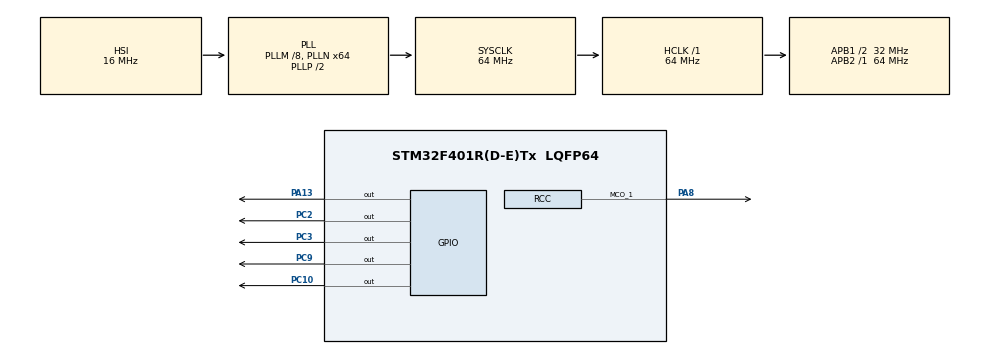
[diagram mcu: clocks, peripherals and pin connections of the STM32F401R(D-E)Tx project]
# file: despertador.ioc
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Mcu.Family=STM32F4
Mcu.Name=STM32F401R(D-E)Tx
Mcu.Package=LQFP64
NVIC.PriorityGroup=NVIC_PRIORITYGROUP_0
NVIC.RTC_WKUP_IRQn=true\:0\:0\:false\:false\:true\:true\:true\:true
PA13.Signal=GPIO_Output
PA8.Mode=Clock-out-1
PA8.Signal=RCC_MCO_1
PC10.Signal=GPIO_Output
PC2.Signal=GPIO_Output
PC3.Signal=GPIO_Output
PC9.Signal=GPIO_Output
ProjectManager.HeapSize=0x200
ProjectManager.StackSize=0x400
ProjectManager.TargetToolchain=STM32CubeIDE
RCC.48MHZClocksFreq_Value=18285714.285714287
RCC.AHBFreq_Value=64000000
RCC.APB1CLKDivider=RCC_HCLK_DIV2
RCC.APB1Freq_Value=32000000
RCC.APB1TimFreq_Value=64000000
RCC.APB2Freq_Value=64000000
RCC.APB2TimFreq_Value=64000000
RCC.CortexFreq_Value=64000000
RCC.HCLKFreq_Value=64000000
RCC.HSE_VALUE=8000000
RCC.HSI_VALUE=16000000
RCC.LSE_VALUE=32768
RCC.PLLM=8
RCC.PLLN=64
RCC.PLLQ=7
RCC.RCC_TIM_PRescaler_Selection=RCC_TIMPRES_DESACTIVATED
RCC.SYSCLKFreq_VALUE=64000000
RCC.SYSCLKSource=RCC_SYSCLKSOURCE_PLLCLK
RCC.VCOOutputFreq_Value=128000000
RTC.Format=RTC_FORMAT_BIN
RTC.Hours=18
RTC.Minutes=18
TIM1.Prescaler=5
VP_RTC_VS_RTC_Activate.Mode=RTC_Enabled
VP_RTC_VS_RTC_Calendar.Mode=RTC_Calendar
VP_RTC_VS_RTC_WakeUp_intern.Mode=WakeUp
VP_TIM1_VS_ClockSourceINT.Mode=Internal
board=NUCLEO-F401RE

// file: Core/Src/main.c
/* USER CODE BEGIN Header */
/**
  ******************************************************************************
  * @file           : main.c
  * @brief          : Main program body
  ******************************************************************************
  * @attention
  *
  * Copyright (c) 2024 STMicroelectronics.
  * All rights reserved.
  *
  * This software is licensed under terms that can be found in the LICENSE file
  * in the root directory of this software component.
  * If no LICENSE file comes with this software, it is provided AS-IS.
  *
  ******************************************************************************
  */
/* USER CODE END Header */
#include "main.h"

/* USER CODE BEGIN Includes */

uint8_t dia, mes, hora, min , seg;

uint8_t segmento;

uint8_t digitos[10] = {0b10011111,0b00100101,0b00001101,
					   0b10011001,0b01001001,0b01000001,
					   0b00011111,0b00000001,0b00001001,0b00000011};

/* USER CODE END Includes */

RTC_HandleTypeDef hrtc;

TIM_HandleTypeDef htim1;

void SystemClock_Config(void);
static void MX_GPIO_Init(void);
static void MX_RTC_Init(void);
static void MX_TIM1_Init(void);

int main(void)
{

  /* MCU Configuration--------------------------------------------------------*/

  /* Reset of all peripherals, Initializes the Flash interface and the Systick. */
  HAL_Init();

  /* Configure the system clock */
  SystemClock_Config();

  /* Initialize all configured peripherals */
  MX_GPIO_Init();
  MX_RTC_Init();
  MX_TIM1_Init();
  /* USER CODE BEGIN 2 */

	RTC_DateTypeDef sDate;
	RTC_TimeTypeDef sTime;

	//mandam um sinal digital para permitir que cada digito do display acenda;
	HAL_GPIO_WritePin(GPIOC, GPIO_PIN_2, 1);
	HAL_GPIO_WritePin(GPIOC, GPIO_PIN_3, 1);

	//manda um sinal 1 para o SRCLR para que os registradores não sejam apagados
	HAL_GPIO_WritePin(GPIOC, GPIO_PIN_10, 1);

	void envia_bit(int sinal){
		HAL_GPIO_WritePin(GPIOA, GPIO_PIN_13, sinal);
	}

	void one_pulse(){
		__HAL_TIM_SET_COUNTER(&htim1,0);

		HAL_TIM_Base_Start(&htim1);
		while(__HAL_TIM_GET_COUNTER(&htim1) < 1);
	    HAL_TIM_Base_Stop(&htim1);
	}

	HAL_RCC_MCOConfig(RCC_MCO1, RCC_MCO2SOURCE_SYSCLK, RCC_MCODIV_5);

	HAL_RTC_GetDate(&hrtc, &sDate, RTC_FORMAT_BIN);
	HAL_RTC_GetTime(&hrtc, &sTime, RTC_FORMAT_BIN);

   dia = sDate.Date;
   mes = sDate.Month;

   hora = sTime.Hours;
   min = sTime.Minutes;
   seg = sTime.Seconds;

   HAL_RTC_SetDate(&hrtc, &sDate, RTC_FORMAT_BIN);
   HAL_RTC_SetTime(&hrtc, &sTime, RTC_FORMAT_BIN);

  /* USER CODE END 2 */

  /* Infinite loop */
  while (1)
  {

    /* USER CODE BEGIN 3 */
		HAL_RTC_GetDate(&hrtc, &sDate, RTC_FORMAT_BIN);

		dia = sDate.Date;
	    mes = sDate.Month;

	    HAL_RTC_GetTime(&hrtc, &sTime, RTC_FORMAT_BIN);
	    hora = sTime.Hours;
	    HAL_RTC_GetTime(&hrtc, &sTime, RTC_FORMAT_BIN);
	    min = sTime.Minutes;
	    HAL_RTC_GetTime(&hrtc, &sTime, RTC_FORMAT_BIN);
	    seg = sTime.Seconds;

	    if(seg >= 10){
	    	sTime.Seconds = 0;
	    }

	    for(int i = 7; i>=0; i--){
	    	segmento = digitos[seg] & (1 << i);
	    	envia_bit(segmento);
	    	one_pulse();

	    }
  }
  /* USER CODE END 3 */
}

void SystemClock_Config(void)
{
  RCC_OscInitTypeDef RCC_OscInitStruct = {0};
  RCC_ClkInitTypeDef RCC_ClkInitStruct = {0};

  /** Configure the main internal regulator output voltage
  */
  __HAL_RCC_PWR_CLK_ENABLE();
  __HAL_PWR_VOLTAGESCALING_CONFIG(PWR_REGULATOR_VOLTAGE_SCALE2);

  /** Initializes the RCC Oscillators according to the specified parameters
  * in the RCC_OscInitTypeDef structure.
  */
  RCC_OscInitStruct.OscillatorType = RCC_OSCILLATORTYPE_HSI|RCC_OSCILLATORTYPE_LSI;
  RCC_OscInitStruct.HSIState = RCC_HSI_ON;
  RCC_OscInitStruct.HSICalibrationValue = RCC_HSICALIBRATION_DEFAULT;
  RCC_OscInitStruct.LSIState = RCC_LSI_ON;
  RCC_OscInitStruct.PLL.PLLState = RCC_PLL_ON;
  RCC_OscInitStruct.PLL.PLLSource = RCC_PLLSOURCE_HSI;
  RCC_OscInitStruct.PLL.PLLM = 8;
  RCC_OscInitStruct.PLL.PLLN = 64;
  RCC_OscInitStruct.PLL.PLLP = RCC_PLLP_DIV2;
  RCC_OscInitStruct.PLL.PLLQ = 7;
  if (HAL_RCC_OscConfig(&RCC_OscInitStruct) != HAL_OK)
  {
    Error_Handler();
  }

  /** Initializes the CPU, AHB and APB buses clocks
  */
  RCC_ClkInitStruct.ClockType = RCC_CLOCKTYPE_HCLK|RCC_CLOCKTYPE_SYSCLK
                              |RCC_CLOCKTYPE_PCLK1|RCC_CLOCKTYPE_PCLK2;
  RCC_ClkInitStruct.SYSCLKSource = RCC_SYSCLKSOURCE_PLLCLK;
  RCC_ClkInitStruct.AHBCLKDivider = RCC_SYSCLK_DIV1;
  RCC_ClkInitStruct.APB1CLKDivider = RCC_HCLK_DIV2;
  RCC_ClkInitStruct.APB2CLKDivider = RCC_HCLK_DIV1;

  if (HAL_RCC_ClockConfig(&RCC_ClkInitStruct, FLASH_LATENCY_2) != HAL_OK)
  {
    Error_Handler();
  }
  HAL_RCC_MCOConfig(RCC_MCO1, RCC_MCO1SOURCE_HSI, RCC_MCODIV_1);
}

static void MX_RTC_Init(void)
{

  RTC_TimeTypeDef sTime = {0};
  RTC_DateTypeDef sDate = {0};

  /** Initialize RTC Only
  */
  hrtc.Instance = RTC;
  hrtc.Init.HourFormat = RTC_HOURFORMAT_24;
  hrtc.Init.AsynchPrediv = 127;
  hrtc.Init.SynchPrediv = 255;
  hrtc.Init.OutPut = RTC_OUTPUT_DISABLE;
  hrtc.Init.OutPutPolarity = RTC_OUTPUT_POLARITY_HIGH;
  hrtc.Init.OutPutType = RTC_OUTPUT_TYPE_OPENDRAIN;
  if (HAL_RTC_Init(&hrtc) != HAL_OK)
  {
    Error_Handler();
  }

  /** Initialize RTC and set the Time and Date
  */
  sTime.Hours = 18;
  sTime.Minutes = 18;
  sTime.Seconds = 0;
  sTime.DayLightSaving = RTC_DAYLIGHTSAVING_NONE;
  sTime.StoreOperation = RTC_STOREOPERATION_RESET;
  if (HAL_RTC_SetTime(&hrtc, &sTime, RTC_FORMAT_BIN) != HAL_OK)
  {
    Error_Handler();
  }
  sDate.WeekDay = RTC_WEEKDAY_MONDAY;
  sDate.Month = RTC_MONTH_JANUARY;
  sDate.Date = 1;
  sDate.Year = 0;

  if (HAL_RTC_SetDate(&hrtc, &sDate, RTC_FORMAT_BIN) != HAL_OK)
  {
    Error_Handler();
  }

  /** Enable the WakeUp
  */
  if (HAL_RTCEx_SetWakeUpTimer_IT(&hrtc, 0, RTC_WAKEUPCLOCK_RTCCLK_DIV16) != HAL_OK)
  {
    Error_Handler();
  }

}

static void MX_TIM1_Init(void)
{

  TIM_ClockConfigTypeDef sClockSourceConfig = {0};
  TIM_MasterConfigTypeDef sMasterConfig = {0};

  htim1.Instance = TIM1;
  htim1.Init.Prescaler = 5;
  htim1.Init.CounterMode = TIM_COUNTERMODE_UP;
  htim1.Init.Period = 65535;
  htim1.Init.ClockDivision = TIM_CLOCKDIVISION_DIV1;
  htim1.Init.RepetitionCounter = 0;
  htim1.Init.AutoReloadPreload = TIM_AUTORELOAD_PRELOAD_DISABLE;
  if (HAL_TIM_Base_Init(&htim1) != HAL_OK)
  {
    Error_Handler();
  }
  sClockSourceConfig.ClockSource = TIM_CLOCKSOURCE_INTERNAL;
  if (HAL_TIM_ConfigClockSource(&htim1, &sClockSourceConfig) != HAL_OK)
  {
    Error_Handler();
  }
  sMasterConfig.MasterOutputTrigger = TIM_TRGO_RESET;
  sMasterConfig.MasterSlaveMode = TIM_MASTERSLAVEMODE_DISABLE;
  if (HAL_TIMEx_MasterConfigSynchronization(&htim1, &sMasterConfig) != HAL_OK)
  {
    Error_Handler();
  }

}

static void MX_GPIO_Init(void)
{
  GPIO_InitTypeDef GPIO_InitStruct = {0};

  /* GPIO Ports Clock Enable */
  __HAL_RCC_GPIOC_CLK_ENABLE();
  __HAL_RCC_GPIOA_CLK_ENABLE();

  /*Configure GPIO pin Output Level */
  HAL_GPIO_WritePin(GPIOC, GPIO_PIN_1|GPIO_PIN_3|GPIO_PIN_9|GPIO_PIN_10, GPIO_PIN_RESET);

  /*Configure GPIO pin Output Level */
  HAL_GPIO_WritePin(GPIOA, GPIO_PIN_13, GPIO_PIN_RESET);

  /*Configure GPIO pins : PC1 PC3 PC9 PC10 */
  GPIO_InitStruct.Pin = GPIO_PIN_1|GPIO_PIN_3|GPIO_PIN_9|GPIO_PIN_10;
  GPIO_InitStruct.Mode = GPIO_MODE_OUTPUT_PP;
  GPIO_InitStruct.Pull = GPIO_NOPULL;
  GPIO_InitStruct.Speed = GPIO_SPEED_FREQ_LOW;
  HAL_GPIO_Init(GPIOC, &GPIO_InitStruct);

  /*Configure GPIO pin : PA8 */
  GPIO_InitStruct.Pin = GPIO_PIN_8;
  GPIO_InitStruct.Mode = GPIO_MODE_AF_PP;
  GPIO_InitStruct.Pull = GPIO_NOPULL;
  GPIO_InitStruct.Speed = GPIO_SPEED_FREQ_LOW;
  GPIO_InitStruct.Alternate = GPIO_AF0_MCO;
  HAL_GPIO_Init(GPIOA, &GPIO_InitStruct);

  /*Configure GPIO pin : PA13 */
  GPIO_InitStruct.Pin = GPIO_PIN_13;
  GPIO_InitStruct.Mode = GPIO_MODE_OUTPUT_PP;
  GPIO_InitStruct.Pull = GPIO_NOPULL;
  GPIO_InitStruct.Speed = GPIO_SPEED_FREQ_LOW;
  HAL_GPIO_Init(GPIOA, &GPIO_InitStruct);

}

void Error_Handler(void)
{
  __disable_irq();
  while (1)
  {
  }
}
